# ESP32-C6 register map
Vendor: ESPRESSIF SYSTEMS (SHANGHAI) CO., LTD.; Series: ESP32 C-Series; File version: 2
CPU: RV32IMC r0p0, little endian, no MPU, no FPU, 4 interrupt priority bits
Address unit: 32 bits
Registers are 32-bit, read-write, reset 0x0 unless marked. A register's access mark holds for its fields unless they carry their own. Offsets are from the block's base; [hi:lo] are bit positions; {n}, {i} and the like mark numbered series.

## SLCHOST — Peripheral SLCHOST
Base 0x60017000
0x10 FUNC2_0 — *******Description***********
  [24] SLC_FUNC2_INT
0x14 FUNC2_1 — *******Description***********
  [0] SLC_FUNC2_INT_EN
0x20 FUNC2_2 reset 0x1 — *******Description***********
  [0] SLC_FUNC1_MDSTAT
0x34 GPIO_STATUS0 ro — *******Description***********
  [31:0] GPIO_SDIO_INT0
0x38 GPIO_STATUS1 ro — *******Description***********
  [31:0] GPIO_SDIO_INT1
0x3C GPIO_IN0 ro — *******Description***********
  [31:0] GPIO_SDIO_IN0
0x40 GPIO_IN1 ro — *******Description***********
  [31:0] GPIO_SDIO_IN1
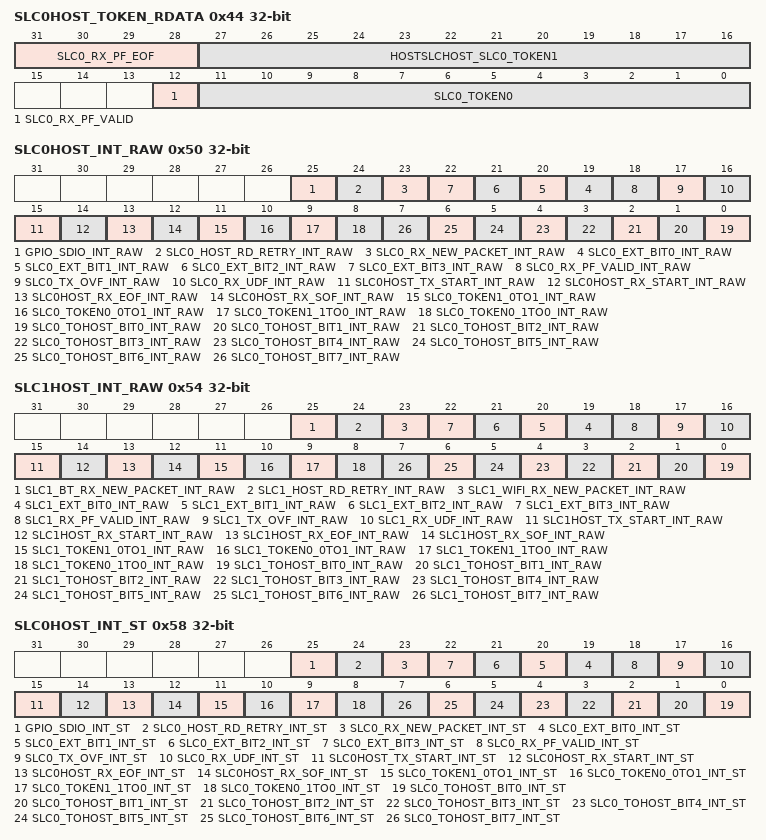
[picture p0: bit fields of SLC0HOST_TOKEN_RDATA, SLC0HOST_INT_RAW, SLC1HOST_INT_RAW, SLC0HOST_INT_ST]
0x44 SLC0HOST_TOKEN_RDATA ro — *******Description***********
  [31:28] SLC0_RX_PF_EOF — *******Description***********
  [27:16] HOSTSLCHOST_SLC0_TOKEN1 — *******Description***********
  [12] SLC0_RX_PF_VALID — *******Description***********
  [11:0] SLC0_TOKEN0 — *******Description***********
0x48 SLC0_HOST_PF ro — *******Description***********
  [31:0] SLC0_PF_DATA
0x4C SLC1_HOST_PF ro — *******Description***********
  [31:0] SLC1_PF_DATA
0x50 SLC0HOST_INT_RAW ro — *******Description***********
  [25] GPIO_SDIO_INT_RAW — *******Description***********
  [24] SLC0_HOST_RD_RETRY_INT_RAW — *******Description***********
  [23] SLC0_RX_NEW_PACKET_INT_RAW — *******Description***********
  [n+19] SLC0_EXT_BIT{n}_INT_RAW (n=0..3) — *******Description***********
  [18] SLC0_RX_PF_VALID_INT_RAW — *******Description***********
  [17] SLC0_TX_OVF_INT_RAW — *******Description***********
  [16] SLC0_RX_UDF_INT_RAW — *******Description***********
  [15] SLC0HOST_TX_START_INT_RAW — *******Description***********
  [14] SLC0HOST_RX_START_INT_RAW — *******Description***********
  [13] SLC0HOST_RX_EOF_INT_RAW — *******Description***********
  [12] SLC0HOST_RX_SOF_INT_RAW — *******Description***********
  [11] SLC0_TOKEN1_0TO1_INT_RAW — *******Description***********
  [10] SLC0_TOKEN0_0TO1_INT_RAW — *******Description***********
  [9] SLC0_TOKEN1_1TO0_INT_RAW — *******Description***********
  [8] SLC0_TOKEN0_1TO0_INT_RAW — *******Description***********
  [n] SLC0_TOHOST_BIT{n}_INT_RAW (n=0..7) — *******Description***********
0x54 SLC1HOST_INT_RAW ro — *******Description***********
  [25] SLC1_BT_RX_NEW_PACKET_INT_RAW — *******Description***********
  [24] SLC1_HOST_RD_RETRY_INT_RAW — *******Description***********
  [23] SLC1_WIFI_RX_NEW_PACKET_INT_RAW — *******Description***********
  [n+19] SLC1_EXT_BIT{n}_INT_RAW (n=0..3) — *******Description***********
  [18] SLC1_RX_PF_VALID_INT_RAW — *******Description***********
  [17] SLC1_TX_OVF_INT_RAW — *******Description***********
  [16] SLC1_RX_UDF_INT_RAW — *******Description***********
  [15] SLC1HOST_TX_START_INT_RAW — *******Description***********
  [14] SLC1HOST_RX_START_INT_RAW — *******Description***********
  [13] SLC1HOST_RX_EOF_INT_RAW — *******Description***********
  [12] SLC1HOST_RX_SOF_INT_RAW — *******Description***********
  [11] SLC1_TOKEN1_0TO1_INT_RAW — *******Description***********
  [10] SLC1_TOKEN0_0TO1_INT_RAW — *******Description***********
  [9] SLC1_TOKEN1_1TO0_INT_RAW — *******Description***********
  [8] SLC1_TOKEN0_1TO0_INT_RAW — *******Description***********
  [n] SLC1_TOHOST_BIT{n}_INT_RAW (n=0..7) — *******Description***********
0x58 SLC0HOST_INT_ST ro — *******Description***********
  [25] GPIO_SDIO_INT_ST — *******Description***********
  [24] SLC0_HOST_RD_RETRY_INT_ST — *******Description***********
  [23] SLC0_RX_NEW_PACKET_INT_ST — *******Description***********
  [n+19] SLC0_EXT_BIT{n}_INT_ST (n=0..3) — *******Description***********
  [18] SLC0_RX_PF_VALID_INT_ST — *******Description***********
  [17] SLC0_TX_OVF_INT_ST — *******Description***********
  [16] SLC0_RX_UDF_INT_ST — *******Description***********
  [15] SLC0HOST_TX_START_INT_ST — *******Description***********
  [14] SLC0HOST_RX_START_INT_ST — *******Description***********
  [13] SLC0HOST_RX_EOF_INT_ST — *******Description***********
  [12] SLC0HOST_RX_SOF_INT_ST — *******Description***********
  [11] SLC0_TOKEN1_0TO1_INT_ST — *******Description***********
  [10] SLC0_TOKEN0_0TO1_INT_ST — *******Description***********
  [9] SLC0_TOKEN1_1TO0_INT_ST — *******Description***********
  [8] SLC0_TOKEN0_1TO0_INT_ST — *******Description***********
  [n] SLC0_TOHOST_BIT{n}_INT_ST (n=0..7) — *******Description***********
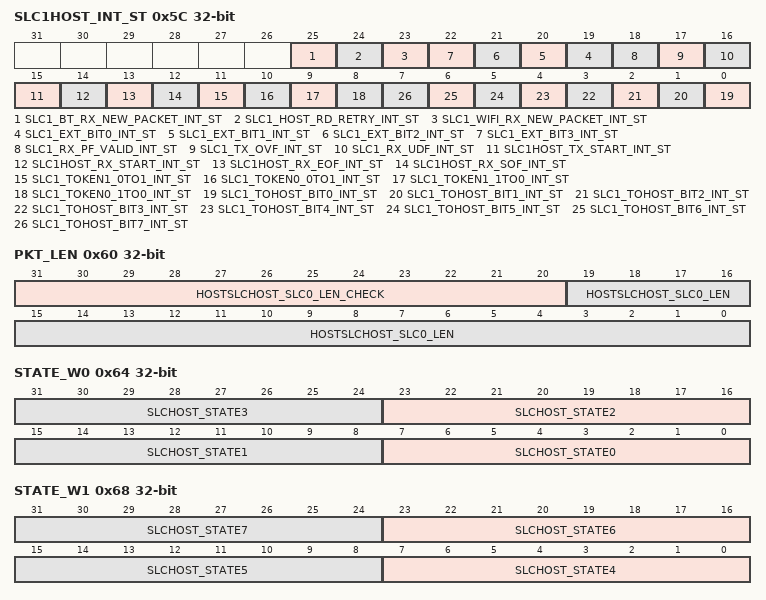
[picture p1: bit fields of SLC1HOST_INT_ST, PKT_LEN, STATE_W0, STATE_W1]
0x5C SLC1HOST_INT_ST ro — *******Description***********
  [25] SLC1_BT_RX_NEW_PACKET_INT_ST — *******Description***********
  [24] SLC1_HOST_RD_RETRY_INT_ST — *******Description***********
  [23] SLC1_WIFI_RX_NEW_PACKET_INT_ST — *******Description***********
  [n+19] SLC1_EXT_BIT{n}_INT_ST (n=0..3) — *******Description***********
  [18] SLC1_RX_PF_VALID_INT_ST — *******Description***********
  [17] SLC1_TX_OVF_INT_ST — *******Description***********
  [16] SLC1_RX_UDF_INT_ST — *******Description***********
  [15] SLC1HOST_TX_START_INT_ST — *******Description***********
  [14] SLC1HOST_RX_START_INT_ST — *******Description***********
  [13] SLC1HOST_RX_EOF_INT_ST — *******Description***********
  [12] SLC1HOST_RX_SOF_INT_ST — *******Description***********
  [11] SLC1_TOKEN1_0TO1_INT_ST — *******Description***********
  [10] SLC1_TOKEN0_0TO1_INT_ST — *******Description***********
  [9] SLC1_TOKEN1_1TO0_INT_ST — *******Description***********
  [8] SLC1_TOKEN0_1TO0_INT_ST — *******Description***********
  [n] SLC1_TOHOST_BIT{n}_INT_ST (n=0..7) — *******Description***********
0x60 PKT_LEN ro — *******Description***********
  [31:20] HOSTSLCHOST_SLC0_LEN_CHECK — *******Description***********
  [19:0] HOSTSLCHOST_SLC0_LEN — *******Description***********
0x64 STATE_W0 ro — *******Description***********
  [8n+7:8n] SLCHOST_STATE{n} (n=0..3) — *******Description***********
0x68 STATE_W1 ro — *******Description***********
  [8n-25:8n-32] SLCHOST_STATE{n} (n=4..7) — *******Description***********
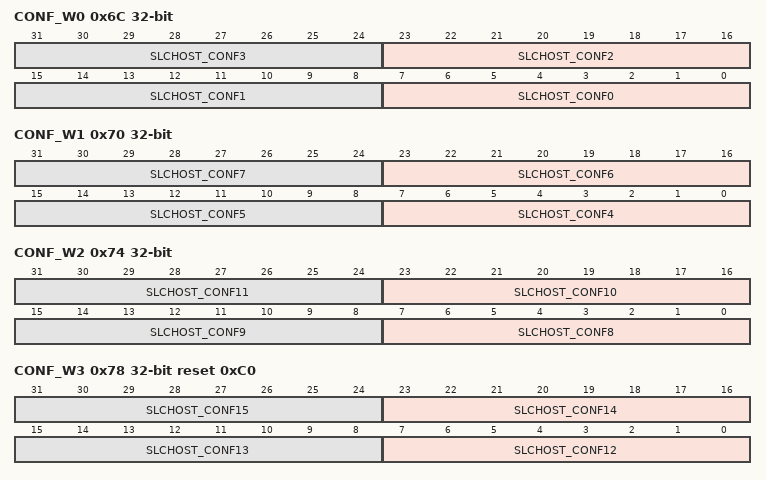
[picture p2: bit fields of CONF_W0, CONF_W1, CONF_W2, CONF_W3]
0x6C CONF_W0 — *******Description***********
  [8n+7:8n] SLCHOST_CONF{n} (n=0..3) — *******Description***********
0x70 CONF_W1 — *******Description***********
  [8n-25:8n-32] SLCHOST_CONF{n} (n=4..7) — *******Description***********
0x74 CONF_W2 — *******Description***********
  [8n-57:8n-64] SLCHOST_CONF{n} (n=8..11) — *******Description***********
0x78 CONF_W3 reset 0xC0 — *******Description***********
  [8n-89:8n-96] SLCHOST_CONF{n} (n=12..15) — *******Description***********
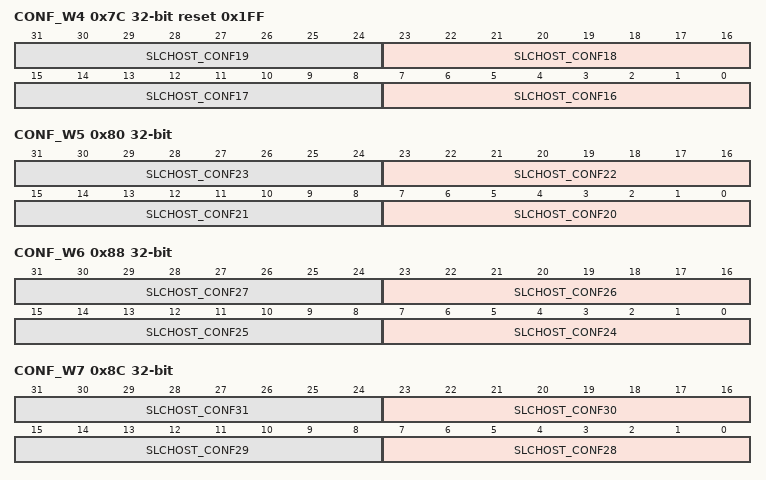
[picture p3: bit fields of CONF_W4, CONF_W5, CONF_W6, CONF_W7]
0x7C CONF_W4 reset 0x1FF — *******Description***********
  [8n-121:8n-128] SLCHOST_CONF{n} (n=16..19) — *******Description***********
0x80 CONF_W5 — *******Description***********
  [8n-153:8n-160] SLCHOST_CONF{n} (n=20..23) — *******Description***********
0x84 WIN_CMD — *******Description***********
  [15:0] SLCHOST_WIN_CMD
0x88 CONF_W6 — *******Description***********
  [8n-185:8n-192] SLCHOST_CONF{n} (n=24..27) — *******Description***********
0x8C CONF_W7 — *******Description***********
  [8n-217:8n-224] SLCHOST_CONF{n} (n=28..31) — *******Description***********
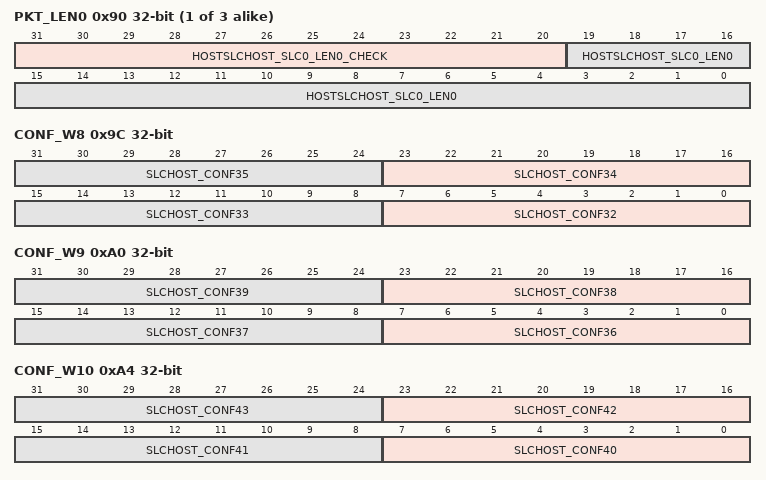
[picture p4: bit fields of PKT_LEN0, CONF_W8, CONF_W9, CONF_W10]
{0x90+4i} PKT_LEN{i} ro (i=0..2) — *******Description***********
  [31:20] HOSTSLCHOST_SLC0_LEN{i}_CHECK — *******Description***********
  [19:0] HOSTSLCHOST_SLC0_LEN{i} — *******Description***********
0x9C CONF_W8 — *******Description***********
  [8n-249:8n-256] SLCHOST_CONF{n} (n=32..35) — *******Description***********
0xA0 CONF_W9 — *******Description***********
  [8n-281:8n-288] SLCHOST_CONF{n} (n=36..39) — *******Description***********
0xA4 CONF_W10 — *******Description***********
  [8n-313:8n-320] SLCHOST_CONF{n} (n=40..43) — *******Description***********
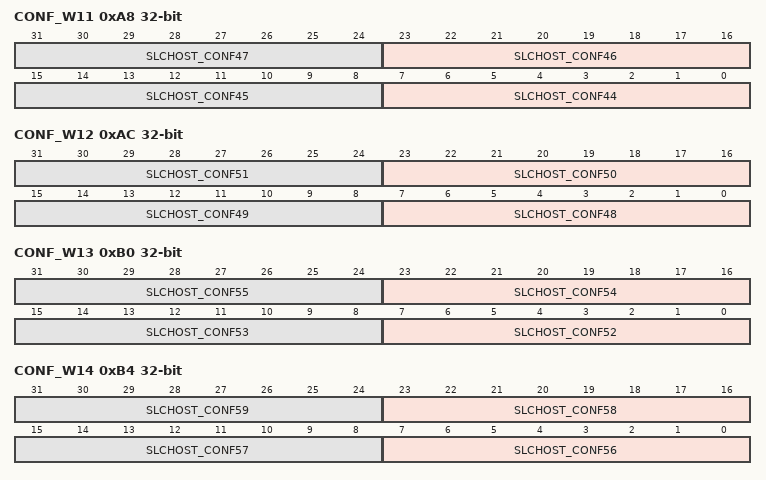
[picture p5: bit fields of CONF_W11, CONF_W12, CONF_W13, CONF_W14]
0xA8 CONF_W11 — *******Description***********
  [8n-345:8n-352] SLCHOST_CONF{n} (n=44..47) — *******Description***********
0xAC CONF_W12 — *******Description***********
  [8n-377:8n-384] SLCHOST_CONF{n} (n=48..51) — *******Description***********
0xB0 CONF_W13 — *******Description***********
  [8n-409:8n-416] SLCHOST_CONF{n} (n=52..55) — *******Description***********
0xB4 CONF_W14 — *******Description***********
  [8n-441:8n-448] SLCHOST_CONF{n} (n=56..59) — *******Description***********
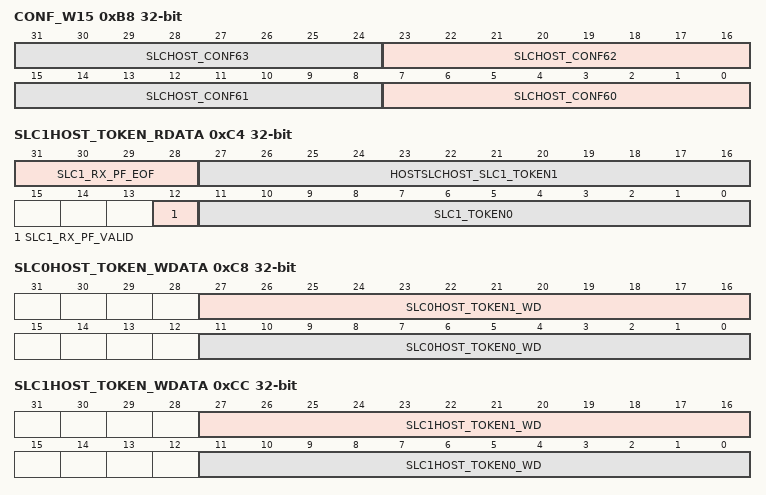
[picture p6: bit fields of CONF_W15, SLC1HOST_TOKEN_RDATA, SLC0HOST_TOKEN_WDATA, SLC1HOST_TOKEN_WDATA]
0xB8 CONF_W15 — *******Description***********
  [8n-473:8n-480] SLCHOST_CONF{n} (n=60..63) — *******Description***********
0xBC CHECK_SUM0 ro — *******Description***********
  [31:0] SLCHOST_CHECK_SUM0
0xC0 CHECK_SUM1 ro reset 0x13F — *******Description***********
  [31:0] SLCHOST_CHECK_SUM1
0xC4 SLC1HOST_TOKEN_RDATA ro — *******Description***********
  [31:28] SLC1_RX_PF_EOF — *******Description***********
  [27:16] HOSTSLCHOST_SLC1_TOKEN1 — *******Description***********
  [12] SLC1_RX_PF_VALID — *******Description***********
  [11:0] SLC1_TOKEN0 — *******Description***********
0xC8 SLC0HOST_TOKEN_WDATA — *******Description***********
  [27:16] SLC0HOST_TOKEN1_WD — *******Description***********
  [11:0] SLC0HOST_TOKEN0_WD — *******Description***********
0xCC SLC1HOST_TOKEN_WDATA — *******Description***********
  [27:16] SLC1HOST_TOKEN1_WD — *******Description***********
  [11:0] SLC1HOST_TOKEN0_WD — *******Description***********
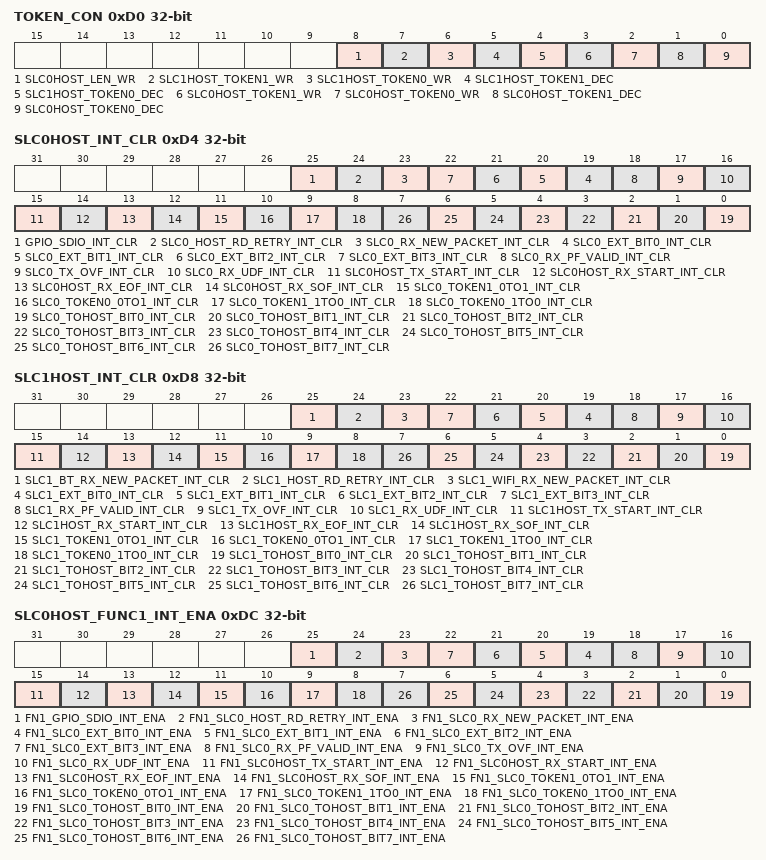
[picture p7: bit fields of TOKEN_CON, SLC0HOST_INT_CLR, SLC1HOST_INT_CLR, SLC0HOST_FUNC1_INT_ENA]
0xD0 TOKEN_CON wo — *******Description***********
  [8] SLC0HOST_LEN_WR — *******Description***********
  [7] SLC1HOST_TOKEN1_WR — *******Description***********
  [6] SLC1HOST_TOKEN0_WR — *******Description***********
  [5] SLC1HOST_TOKEN1_DEC — *******Description***********
  [4] SLC1HOST_TOKEN0_DEC — *******Description***********
  [3] SLC0HOST_TOKEN1_WR — *******Description***********
  [2] SLC0HOST_TOKEN0_WR — *******Description***********
  [1] SLC0HOST_TOKEN1_DEC — *******Description***********
  [0] SLC0HOST_TOKEN0_DEC — *******Description***********
0xD4 SLC0HOST_INT_CLR wo — *******Description***********
  [25] GPIO_SDIO_INT_CLR — *******Description***********
  [24] SLC0_HOST_RD_RETRY_INT_CLR — *******Description***********
  [23] SLC0_RX_NEW_PACKET_INT_CLR — *******Description***********
  [n+19] SLC0_EXT_BIT{n}_INT_CLR (n=0..3) — *******Description***********
  [18] SLC0_RX_PF_VALID_INT_CLR — *******Description***********
  [17] SLC0_TX_OVF_INT_CLR — *******Description***********
  [16] SLC0_RX_UDF_INT_CLR — *******Description***********
  [15] SLC0HOST_TX_START_INT_CLR — *******Description***********
  [14] SLC0HOST_RX_START_INT_CLR — *******Description***********
  [13] SLC0HOST_RX_EOF_INT_CLR — *******Description***********
  [12] SLC0HOST_RX_SOF_INT_CLR — *******Description***********
  [11] SLC0_TOKEN1_0TO1_INT_CLR — *******Description***********
  [10] SLC0_TOKEN0_0TO1_INT_CLR — *******Description***********
  [9] SLC0_TOKEN1_1TO0_INT_CLR — *******Description***********
  [8] SLC0_TOKEN0_1TO0_INT_CLR — *******Description***********
  [n] SLC0_TOHOST_BIT{n}_INT_CLR (n=0..7) — *******Description***********
0xD8 SLC1HOST_INT_CLR wo — *******Description***********
  [25] SLC1_BT_RX_NEW_PACKET_INT_CLR — *******Description***********
  [24] SLC1_HOST_RD_RETRY_INT_CLR — *******Description***********
  [23] SLC1_WIFI_RX_NEW_PACKET_INT_CLR — *******Description***********
  [n+19] SLC1_EXT_BIT{n}_INT_CLR (n=0..3) — *******Description***********
  [18] SLC1_RX_PF_VALID_INT_CLR — *******Description***********
  [17] SLC1_TX_OVF_INT_CLR — *******Description***********
  [16] SLC1_RX_UDF_INT_CLR — *******Description***********
  [15] SLC1HOST_TX_START_INT_CLR — *******Description***********
  [14] SLC1HOST_RX_START_INT_CLR — *******Description***********
  [13] SLC1HOST_RX_EOF_INT_CLR — *******Description***********
  [12] SLC1HOST_RX_SOF_INT_CLR — *******Description***********
  [11] SLC1_TOKEN1_0TO1_INT_CLR — *******Description***********
  [10] SLC1_TOKEN0_0TO1_INT_CLR — *******Description***********
  [9] SLC1_TOKEN1_1TO0_INT_CLR — *******Description***********
  [8] SLC1_TOKEN0_1TO0_INT_CLR — *******Description***********
  [n] SLC1_TOHOST_BIT{n}_INT_CLR (n=0..7) — *******Description***********
0xDC SLC0HOST_FUNC1_INT_ENA — *******Description***********
  [25] FN1_GPIO_SDIO_INT_ENA — *******Description***********
  [24] FN1_SLC0_HOST_RD_RETRY_INT_ENA — *******Description***********
  [23] FN1_SLC0_RX_NEW_PACKET_INT_ENA — *******Description***********
  [n+19] FN1_SLC0_EXT_BIT{n}_INT_ENA (n=0..3) — *******Description***********
  [18] FN1_SLC0_RX_PF_VALID_INT_ENA — *******Description***********
  [17] FN1_SLC0_TX_OVF_INT_ENA — *******Description***********
  [16] FN1_SLC0_RX_UDF_INT_ENA — *******Description***********
  [15] FN1_SLC0HOST_TX_START_INT_ENA — *******Description***********
  [14] FN1_SLC0HOST_RX_START_INT_ENA — *******Description***********
  [13] FN1_SLC0HOST_RX_EOF_INT_ENA — *******Description***********
  [12] FN1_SLC0HOST_RX_SOF_INT_ENA — *******Description***********
  [11] FN1_SLC0_TOKEN1_0TO1_INT_ENA — *******Description***********
  [10] FN1_SLC0_TOKEN0_0TO1_INT_ENA — *******Description***********
  [9] FN1_SLC0_TOKEN1_1TO0_INT_ENA — *******Description***********
  [8] FN1_SLC0_TOKEN0_1TO0_INT_ENA — *******Description***********
  [n] FN1_SLC0_TOHOST_BIT{n}_INT_ENA (n=0..7) — *******Description***********
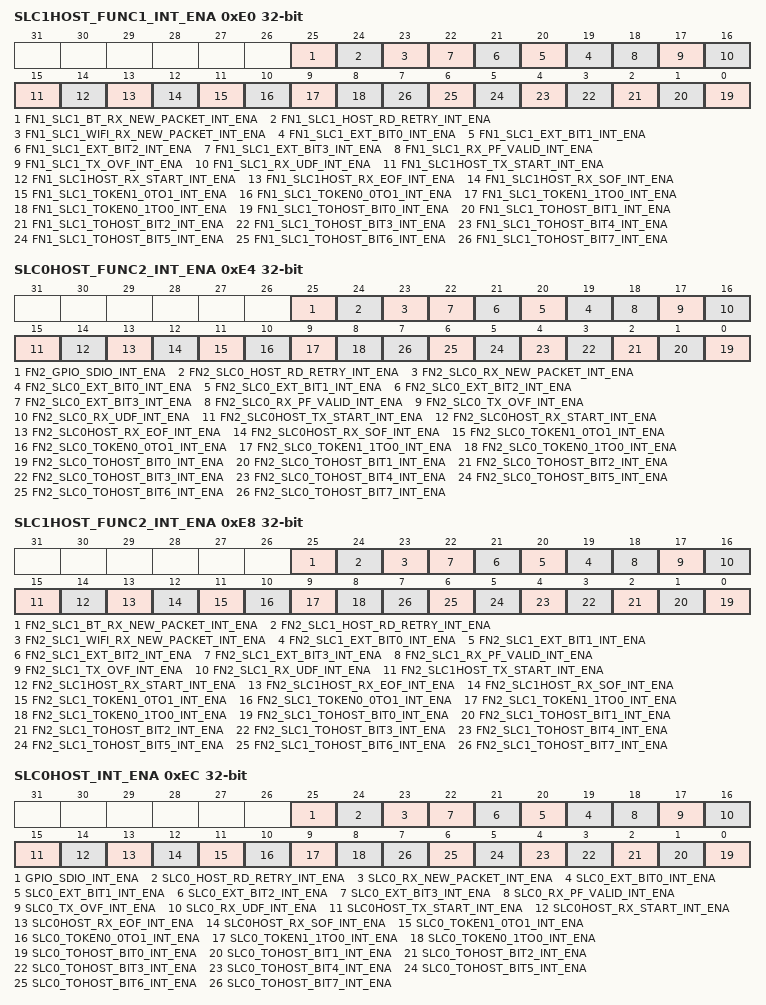
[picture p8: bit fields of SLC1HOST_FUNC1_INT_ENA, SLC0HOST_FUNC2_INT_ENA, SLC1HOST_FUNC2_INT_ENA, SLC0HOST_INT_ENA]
0xE0 SLC1HOST_FUNC1_INT_ENA — *******Description***********
  [25] FN1_SLC1_BT_RX_NEW_PACKET_INT_ENA — *******Description***********
  [24] FN1_SLC1_HOST_RD_RETRY_INT_ENA — *******Description***********
  [23] FN1_SLC1_WIFI_RX_NEW_PACKET_INT_ENA — *******Description***********
  [n+19] FN1_SLC1_EXT_BIT{n}_INT_ENA (n=0..3) — *******Description***********
  [18] FN1_SLC1_RX_PF_VALID_INT_ENA — *******Description***********
  [17] FN1_SLC1_TX_OVF_INT_ENA — *******Description***********
  [16] FN1_SLC1_RX_UDF_INT_ENA — *******Description***********
  [15] FN1_SLC1HOST_TX_START_INT_ENA — *******Description***********
  [14] FN1_SLC1HOST_RX_START_INT_ENA — *******Description***********
  [13] FN1_SLC1HOST_RX_EOF_INT_ENA — *******Description***********
  [12] FN1_SLC1HOST_RX_SOF_INT_ENA — *******Description***********
  [11] FN1_SLC1_TOKEN1_0TO1_INT_ENA — *******Description***********
  [10] FN1_SLC1_TOKEN0_0TO1_INT_ENA — *******Description***********
  [9] FN1_SLC1_TOKEN1_1TO0_INT_ENA — *******Description***********
  [8] FN1_SLC1_TOKEN0_1TO0_INT_ENA — *******Description***********
  [n] FN1_SLC1_TOHOST_BIT{n}_INT_ENA (n=0..7) — *******Description***********
0xE4 SLC0HOST_FUNC2_INT_ENA — *******Description***********
  [25] FN2_GPIO_SDIO_INT_ENA — *******Description***********
  [24] FN2_SLC0_HOST_RD_RETRY_INT_ENA — *******Description***********
  [23] FN2_SLC0_RX_NEW_PACKET_INT_ENA — *******Description***********
  [n+19] FN2_SLC0_EXT_BIT{n}_INT_ENA (n=0..3) — *******Description***********
  [18] FN2_SLC0_RX_PF_VALID_INT_ENA — *******Description***********
  [17] FN2_SLC0_TX_OVF_INT_ENA — *******Description***********
  [16] FN2_SLC0_RX_UDF_INT_ENA — *******Description***********
  [15] FN2_SLC0HOST_TX_START_INT_ENA — *******Description***********
  [14] FN2_SLC0HOST_RX_START_INT_ENA — *******Description***********
  [13] FN2_SLC0HOST_RX_EOF_INT_ENA — *******Description***********
  [12] FN2_SLC0HOST_RX_SOF_INT_ENA — *******Description***********
  [11] FN2_SLC0_TOKEN1_0TO1_INT_ENA — *******Description***********
  [10] FN2_SLC0_TOKEN0_0TO1_INT_ENA — *******Description***********
  [9] FN2_SLC0_TOKEN1_1TO0_INT_ENA — *******Description***********
  [8] FN2_SLC0_TOKEN0_1TO0_INT_ENA — *******Description***********
  [n] FN2_SLC0_TOHOST_BIT{n}_INT_ENA (n=0..7) — *******Description***********
0xE8 SLC1HOST_FUNC2_INT_ENA — *******Description***********
  [25] FN2_SLC1_BT_RX_NEW_PACKET_INT_ENA — *******Description***********
  [24] FN2_SLC1_HOST_RD_RETRY_INT_ENA — *******Description***********
  [23] FN2_SLC1_WIFI_RX_NEW_PACKET_INT_ENA — *******Description***********
  [n+19] FN2_SLC1_EXT_BIT{n}_INT_ENA (n=0..3) — *******Description***********
  [18] FN2_SLC1_RX_PF_VALID_INT_ENA — *******Description***********
  [17] FN2_SLC1_TX_OVF_INT_ENA — *******Description***********
  [16] FN2_SLC1_RX_UDF_INT_ENA — *******Description***********
  [15] FN2_SLC1HOST_TX_START_INT_ENA — *******Description***********
  [14] FN2_SLC1HOST_RX_START_INT_ENA — *******Description***********
  [13] FN2_SLC1HOST_RX_EOF_INT_ENA — *******Description***********
  [12] FN2_SLC1HOST_RX_SOF_INT_ENA — *******Description***********
  [11] FN2_SLC1_TOKEN1_0TO1_INT_ENA — *******Description***********
  [10] FN2_SLC1_TOKEN0_0TO1_INT_ENA — *******Description***********
  [9] FN2_SLC1_TOKEN1_1TO0_INT_ENA — *******Description***********
  [8] FN2_SLC1_TOKEN0_1TO0_INT_ENA — *******Description***********
  [n] FN2_SLC1_TOHOST_BIT{n}_INT_ENA (n=0..7) — *******Description***********
0xEC SLC0HOST_INT_ENA — *******Description***********
  [25] GPIO_SDIO_INT_ENA — *******Description***********
  [24] SLC0_HOST_RD_RETRY_INT_ENA — *******Description***********
  [23] SLC0_RX_NEW_PACKET_INT_ENA — *******Description***********
  [n+19] SLC0_EXT_BIT{n}_INT_ENA (n=0..3) — *******Description***********
  [18] SLC0_RX_PF_VALID_INT_ENA — *******Description***********
  [17] SLC0_TX_OVF_INT_ENA — *******Description***********
  [16] SLC0_RX_UDF_INT_ENA — *******Description***********
  [15] SLC0HOST_TX_START_INT_ENA — *******Description***********
  [14] SLC0HOST_RX_START_INT_ENA — *******Description***********
  [13] SLC0HOST_RX_EOF_INT_ENA — *******Description***********
  [12] SLC0HOST_RX_SOF_INT_ENA — *******Description***********
  [11] SLC0_TOKEN1_0TO1_INT_ENA — *******Description***********
  [10] SLC0_TOKEN0_0TO1_INT_ENA — *******Description***********
  [9] SLC0_TOKEN1_1TO0_INT_ENA — *******Description***********
  [8] SLC0_TOKEN0_1TO0_INT_ENA — *******Description***********
  [n] SLC0_TOHOST_BIT{n}_INT_ENA (n=0..7) — *******Description***********
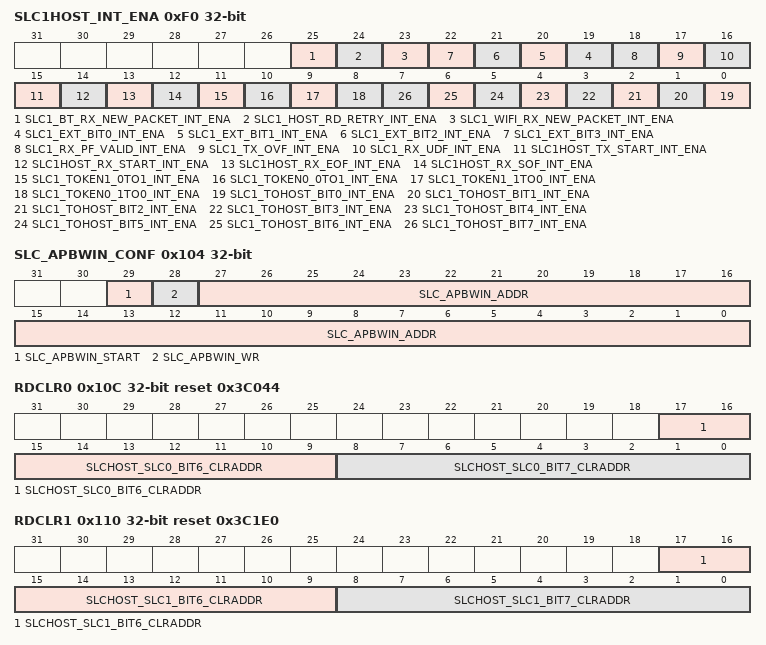
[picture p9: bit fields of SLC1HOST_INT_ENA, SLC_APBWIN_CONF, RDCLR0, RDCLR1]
0xF0 SLC1HOST_INT_ENA — *******Description***********
  [25] SLC1_BT_RX_NEW_PACKET_INT_ENA — *******Description***********
  [24] SLC1_HOST_RD_RETRY_INT_ENA — *******Description***********
  [23] SLC1_WIFI_RX_NEW_PACKET_INT_ENA — *******Description***********
  [n+19] SLC1_EXT_BIT{n}_INT_ENA (n=0..3) — *******Description***********
  [18] SLC1_RX_PF_VALID_INT_ENA — *******Description***********
  [17] SLC1_TX_OVF_INT_ENA — *******Description***********
  [16] SLC1_RX_UDF_INT_ENA — *******Description***********
  [15] SLC1HOST_TX_START_INT_ENA — *******Description***********
  [14] SLC1HOST_RX_START_INT_ENA — *******Description***********
  [13] SLC1HOST_RX_EOF_INT_ENA — *******Description***********
  [12] SLC1HOST_RX_SOF_INT_ENA — *******Description***********
  [11] SLC1_TOKEN1_0TO1_INT_ENA — *******Description***********
  [10] SLC1_TOKEN0_0TO1_INT_ENA — *******Description***********
  [9] SLC1_TOKEN1_1TO0_INT_ENA — *******Description***********
  [8] SLC1_TOKEN0_1TO0_INT_ENA — *******Description***********
  [n] SLC1_TOHOST_BIT{n}_INT_ENA (n=0..7) — *******Description***********
0xF4 SLC0HOST_RX_INFOR — *******Description***********
  [19:0] SLC0HOST_RX_INFOR
0xF8 SLC1HOST_RX_INFOR — *******Description***********
  [19:0] SLC1HOST_RX_INFOR
0xFC SLC0HOST_LEN_WD — *******Description***********
0x100 SLC_APBWIN_WDATA — *******Description***********
0x104 SLC_APBWIN_CONF — *******Description***********
  [29] SLC_APBWIN_START — *******Description***********
  [28] SLC_APBWIN_WR — *******Description***********
  [27:0] SLC_APBWIN_ADDR — *******Description***********
0x108 SLC_APBWIN_RDATA ro — *******Description***********
0x10C RDCLR0 reset 0x3C044 — *******Description***********
  [17:9] SLCHOST_SLC0_BIT6_CLRADDR — *******Description***********
  [8:0] SLCHOST_SLC0_BIT7_CLRADDR — *******Description***********
0x110 RDCLR1 reset 0x3C1E0 — *******Description***********
  [17:9] SLCHOST_SLC1_BIT6_CLRADDR — *******Description***********
  [8:0] SLCHOST_SLC1_BIT7_CLRADDR — *******Description***********
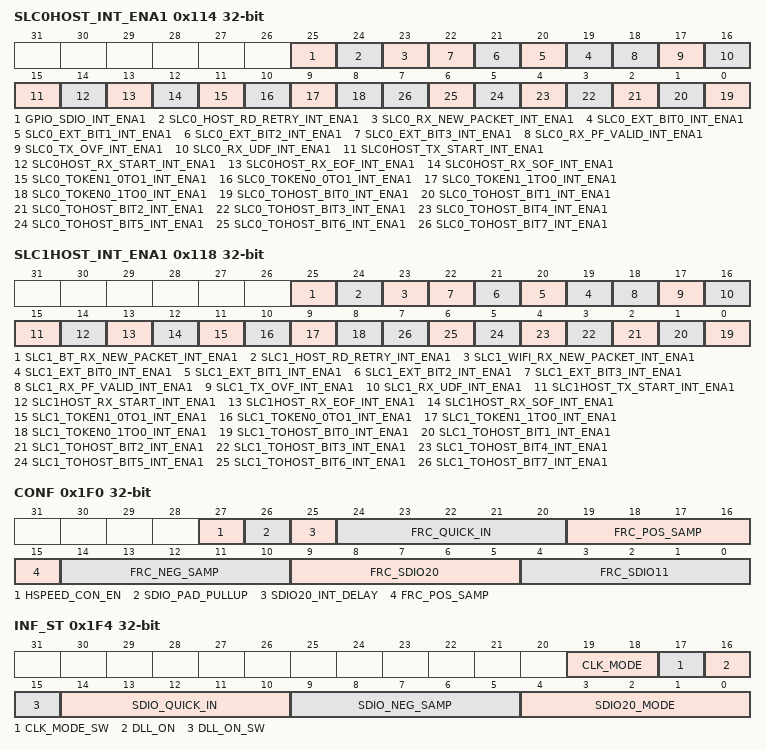
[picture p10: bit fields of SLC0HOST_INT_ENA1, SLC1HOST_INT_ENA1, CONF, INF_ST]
0x114 SLC0HOST_INT_ENA1 — *******Description***********
  [25] GPIO_SDIO_INT_ENA1 — *******Description***********
  [24] SLC0_HOST_RD_RETRY_INT_ENA1 — *******Description***********
  [23] SLC0_RX_NEW_PACKET_INT_ENA1 — *******Description***********
  [n+19] SLC0_EXT_BIT{n}_INT_ENA1 (n=0..3) — *******Description***********
  [18] SLC0_RX_PF_VALID_INT_ENA1 — *******Description***********
  [17] SLC0_TX_OVF_INT_ENA1 — *******Description***********
  [16] SLC0_RX_UDF_INT_ENA1 — *******Description***********
  [15] SLC0HOST_TX_START_INT_ENA1 — *******Description***********
  [14] SLC0HOST_RX_START_INT_ENA1 — *******Description***********
  [13] SLC0HOST_RX_EOF_INT_ENA1 — *******Description***********
  [12] SLC0HOST_RX_SOF_INT_ENA1 — *******Description***********
  [11] SLC0_TOKEN1_0TO1_INT_ENA1 — *******Description***********
  [10] SLC0_TOKEN0_0TO1_INT_ENA1 — *******Description***********
  [9] SLC0_TOKEN1_1TO0_INT_ENA1 — *******Description***********
  [8] SLC0_TOKEN0_1TO0_INT_ENA1 — *******Description***********
  [n] SLC0_TOHOST_BIT{n}_INT_ENA1 (n=0..7) — *******Description***********
0x118 SLC1HOST_INT_ENA1 — *******Description***********
  [25] SLC1_BT_RX_NEW_PACKET_INT_ENA1 — *******Description***********
  [24] SLC1_HOST_RD_RETRY_INT_ENA1 — *******Description***********
  [23] SLC1_WIFI_RX_NEW_PACKET_INT_ENA1 — *******Description***********
  [n+19] SLC1_EXT_BIT{n}_INT_ENA1 (n=0..3) — *******Description***********
  [18] SLC1_RX_PF_VALID_INT_ENA1 — *******Description***********
  [17] SLC1_TX_OVF_INT_ENA1 — *******Description***********
  [16] SLC1_RX_UDF_INT_ENA1 — *******Description***********
  [15] SLC1HOST_TX_START_INT_ENA1 — *******Description***********
  [14] SLC1HOST_RX_START_INT_ENA1 — *******Description***********
  [13] SLC1HOST_RX_EOF_INT_ENA1 — *******Description***********
  [12] SLC1HOST_RX_SOF_INT_ENA1 — *******Description***********
  [11] SLC1_TOKEN1_0TO1_INT_ENA1 — *******Description***********
  [10] SLC1_TOKEN0_0TO1_INT_ENA1 — *******Description***********
  [9] SLC1_TOKEN1_1TO0_INT_ENA1 — *******Description***********
  [8] SLC1_TOKEN0_1TO0_INT_ENA1 — *******Description***********
  [n] SLC1_TOHOST_BIT{n}_INT_ENA1 (n=0..7) — *******Description***********
0x178 SLCHOSTDATE reset 0x21060700 — *******Description***********
  [31:0] SLCHOST_DATE
0x17C SLCHOSTID reset 0x600 — *******Description***********
  [31:0] SLCHOST_ID
0x1F0 CONF — *******Description***********
  [27] HSPEED_CON_EN — *******Description***********
  [26] SDIO_PAD_PULLUP — *******Description***********
  [25] SDIO20_INT_DELAY — *******Description***********
  [24:20] FRC_QUICK_IN — *******Description***********
  [19:15] FRC_POS_SAMP — *******Description***********
  [14:10] FRC_NEG_SAMP — *******Description***********
  [9:5] FRC_SDIO20 — *******Description***********
  [4:0] FRC_SDIO11 — *******Description***********
0x1F4 INF_ST access per field — *******Description***********
  [19:18] CLK_MODE rw — Software set clock mode
  [17] CLK_MODE_SW rw — dll clock mode is controlled by software
  [16] DLL_ON rw — Software dll on
  [15] DLL_ON_SW rw — dll is controlled by software
  [14:10] SDIO_QUICK_IN ro — *******Description***********
  [9:5] SDIO_NEG_SAMP ro — *******Description***********
  [4:0] SDIO20_MODE ro — *******Description***********
